# CEC1736_S0_2HW device description
Architecture: CORTEX-M4; Family: CEC173X; Series: CEC
Registers are 32-bit, read-write, reset 0x0 unless marked. A register's access mark holds for its fields unless they carry their own. Offsets are from the block's base; [hi:lo] are bit positions; lines under a group give offsets from that group; {n}, {i} and the like mark numbered series; 'fields as' and 'values as' point back to an identical list.

## SPI_MON — SPI Monitor Block
Instances: SPI_MON0 0x40010000, SPI_MON1 0x40010400
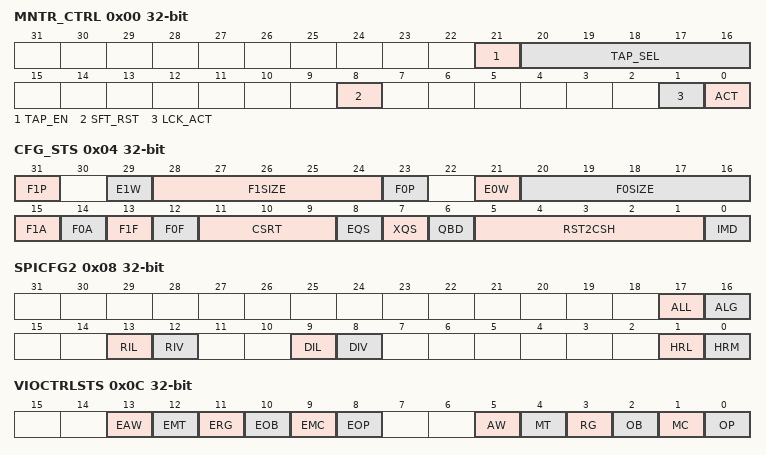
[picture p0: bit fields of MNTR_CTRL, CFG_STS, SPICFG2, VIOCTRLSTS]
0x00 MNTR_CTRL — SPI Monitor Control Register
  [21] TAP_EN — CPTR_CLK_TAP_EN enable the delay taps. It is recommended that a customer set the TAP_EN bit to 1, and the TAP_SEL field to 04h.
  [20:16] TAP_SEL — CPTR_CLK_TAP_SEL selects which 0.5ns delay tap to have the capture clock on. 00h = 0 ns delay (or if TAP_EN = 0). 01h = 0.5ns nom delay; +/- 50% 02h = 1.0ns 03h = 1.5ns 04h = 2.0ns etc. 1Fh = 15.5ns
  [8] SFT_RST — Soft Reset. This field is auto cleared by hardware. 1= Soft Reset SPI Monitor, 0 = No Effect
  [1] LCK_ACT — Lock Activate 1= Activate field Locked, 0= Activate field unlocked
  [0] ACT — Activate 1= Activate, 0= De-activate
0x04 CFG_STS — SPI Configuration Status Register
  [31] F1P — Flash 1 Present. 0=Not Present, 1=Present
  [29] E1W — Enable Wrap Detection. 0=Disable, 1=Enable
  [28:24] F1SIZE — Flash 1 Size. Flash sizes are expressed in bytes as a power of 2, matching a Flash Get-ID convention. For the most common cases: 17h = 23d => 2^23 = 8MByte 18h = 24d => 2^24 = 16MByte 19h = 25d => 2^25 = 32MByte 1Ah = 26d => 2^26 = 64MByte
  [23] F0P — Flash 0 Present. 0=Not Present, 1=Present
  [21] E0W — Enable Wrap Detection. 0=Disable, 1=Enable.
  [20:16] F0SIZE — Flash 0 Size. Flash sizes are expressed in bytes as a power of 2, matching a Flash Get-ID convention. For the most common cases: 17h = 23d => 2^23 = 8MByte 18h = 24d => 2^24 = 16MByte 19h = 25d => 2^25 = 32MByte 1Ah = 26d => 2^26 = 64MByte
  [15] F1A — Set 3B/4B Address Mode for Flash 1. 0=3B Address Mode, 1=4B Address Mode
  [14] F0A — Set 3B/4B Address Mode for Flash 0. 0=3B Address Mode, 1=4B Address Mode
  [13] F1F — Enable following of Address Mode. (SPI Snooping) for each Flash. 0=Disable, 1=Enable
  [12] F0F — Enable following of Address Mode. (SPI Snooping) for each Flash. 0=Disable, 1=Enable
  [11:9] CSRT — Chip Select Routing. 000 = Both CSn#_In pass directly to CSn# Out, both enabled out. 001 = CS1n_In passes to CS1# Output, but CS0# Output is disabled (floats high). 010 = CS0n_In passes to CS0# Output, but CS1# Output is disabled (floats high). 100 = Swap CS1#/CS0#_In to CS0#/CS1# Out respectively, both enabled out. 101 = CS0n_In passes to CS1# Out, and CS0# Output is disabled (floats high). 110 = CS1n_In passes to CS0# Out, and CS1# Output is disabled (floats high). x11 = CS0n/CS1n Outputs are both disabled (floating high) regardless of inputs.
  [8] EQS — Enable Q-Switch (Isolator) to Host. 0 = Disable, 1 = Enable.
  [7] XQS — Cross-Over Q-Switch status. (BMC->CPU). RO image of Interbus bit which as 1 overrides EQS bit at both SPI buses without changing their states.
  [6] QBD — Quad Bus Disable, 1 = Half Bus Mode, 0 = IO[3:0] are all controlled by EQS.
  [5:1] RST2CSH — RESET# to CS# High Delay. 2^n x 20us, 00h=20us, 1Fh= 1.3sec. IRQ triggers at this point also.
  [0] IMD — Flash Intervention Mode. 0 = Power-Off (POR), 1 = RESET# Pulse
0x08 SPICFG2 — SPI Monitor Configuration 2 Register
  [17] ALL — ALG Bit Lock. 0 = Unlocked, 1 = Locked.
  [16] ALG — Hash Algorithm Mode. 0 = SHA-384, 1 = Reserved
  [13] RIL — RIV Bit Lock. 0 = Unlocked, 1 = Locked.
  [12] RIV — Special Region InterVention Mode. If DIV=1 then RIV is ignored. If DIV=0 and RIV=1 then: Reads that are forbidden by the Runtime Region register set are only cancelled by gating off CSn# for that SPI command, and setting the IRQ. No system shutdown results, and subsequent legal Reads are allowed.
  [9] DIL — DIV Bit Lock. 0 = Unlocked, 1 = Locked.
  [8] DIV — Disable Inter Vention. 1 = IRQ-only Mode.
  [1] HRL — HRM Bit Lock. 0 = Unlocked, 1 = Locked.
  [0] HRM — Host Reset Mode. 0 = APn_RESET#, 1 = Pin.
0x0C VIOCTRLSTS — Violation IRQ Control/Status Register
  [13] EAW — Enable Address Wrap within a Flash device Interrupt. 0 = Disable, 1 = Enable
  [12] EMT — Enable Timeout in Match Phase Interrupt. 0 = Disable, 1 = Enable
  [11] ERG — Enable Runtime Region R/W Permission Violation Interrupt. 0 = Disable, 1 = Enable
  [10] EOB — Enable Out of Bounds Interrupt. 0 = Disable, 1 = Enable
  [9] EMC — Enable Data Mismatch Violation Interrupt. 0 = Disable, 1 = Enable
  [8] EOP — Enable Opcode Violation Interrupt. 0 = Disable, 1 = Enable
  [5] AW — Address Wrap within a Flash device.
  [4] MT — Timeout in Match Phase
  [3] RG — Runtime Region R/W Permission Violation
  [2] OB — Out of Bounds. Outside all Runtime Regions
  [1] MC — Data Mismatch Violation
  [0] OP — Opcode Violation
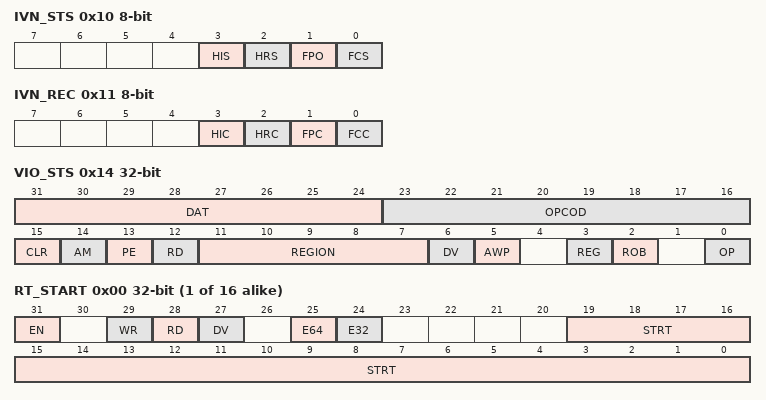
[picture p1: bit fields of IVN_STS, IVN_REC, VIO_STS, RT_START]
0x10 IVN_STS 8-bit ro — SPI Intervention Status Register
  [3] HIS — Host held Isolated
  [2] HRS — Host held in Reset
  [1] FPO — Flash Power or RESET# Activated.
  [0] FCS — Flash Chip Selects forced high and bus forced low.
0x11 IVN_REC 8-bit wo — SPI Intervention Recovery Register
  [3] HIC — Write 1 to clear HIS Host held Isolated
  [2] HRC — Write 1 to clear HRS Host held in Reset
  [1] FPC — Write 1 to clear FPO Flash Power or RESET# Activated.
  [0] FCC — Write 1 to clear FCS Flash Chip Selects forced high and bus forced low.
0x14 VIO_STS — Violation Log Register
  [31:24] DAT — SPI Data Byte
  [23:16] OPCOD — Flash Opcode
  [15] CLR — Clear Register RW1C. This bit is auto clearing
  [14] AM — Flash Address Mode
  [13] PE — Killed as a Program or Erase
  [12] RD — Killed as a Read
  [11:7] REGION — Region Number
  [6] DV — Device Number
  [5] AWP — Address Wrap
  [3] REG — Runtime Region Violation
  [2] ROB — Region Failure, Out of Bounds
  [0] OP — Opcode Violation
0x18 ERR_ADDR ro — Error Byte Address Register
  [31:0] ADDR — Byte address at which the error occurred, within the designated Flash
{0x20+0x80*i} FLASH_SET[{i}] (i=0..1) group — Per Flash Device Register Definition
  {0x0+4j} OP_PRMT[{j}] (j=0..7) — Permit Address Register
    [31:0] PRMT — Permit. Each array organized into 8 32-bit registers set per Flash device. 1 = Permit, and if not recognized then ignore. 0 = Kill immediately upon seeing this opcode.
  {0x20+4j} OP_KILLMD[{j}] (j=0..7) — Kill Address Register
    [31:0] KILL — Kill. Each array organized into 8 32-bit registers set per Flash device. 1 = If Killed, then kill as a Write: Holding CS# low. 0 = If Killed, then kill as a Read: Force CS# high first.
  {0x40+4j} OP_WPROT[{j}] (j=0..7) — Write Protect Address Register
    [31:0] WPROT — Write Protect. Each array organized into 8 32-bit registers set per Flash device. 1 = Make the corresponding bits RO in Permit and Killmd regs. 0 = Corresponding bits are R/W.
  {0x60+4j} OP_LOCK[{j}] (j=0..7) — Lock Address Register
    [31:0] LOCK — Lock. Each array organized into 8 32-bit registers set per Flash device. 1 = Make the corresponding bits RO in Permit and Killmd regs, overriding the Wprot register. Any 1 bit in this register is locked. 0 = Corresponding bits are R/W or RO, as determined by the Wprot register.
{0x120+8i} RN_TM[{i}] (i=0..15) group — Run Time Registers
  0x00 RT_START — Runtime Monitoring Start Register
    [31] EN — Enable Register Pair for Monitoring. 0 = No, 1 = Yes
    [29] WR — Write Allowed for Region. 0 = No, 1 = Yes
    [28] RD — Read Allowed for Region. 0 = No, 1 = Yes
    [27] DV — Flash Device 0 = CS0#, 1 = CS1#.
    [25] E64 — Enable 64KByte Erase opcode for this region. 0 = Disable, 1 = Enable
    [24] E32 — Enable 32KByte Erase opcode for this region. 0 = Disable, 1 = Enable
    [19:0] STRT — A Flash address shifted by 12 (4K byte units). Bottom 12 address bits are 000h
  0x04 RT_LIMIT — Runtime Monitoring Limit Register
    [19:0] LMT — Limit Register
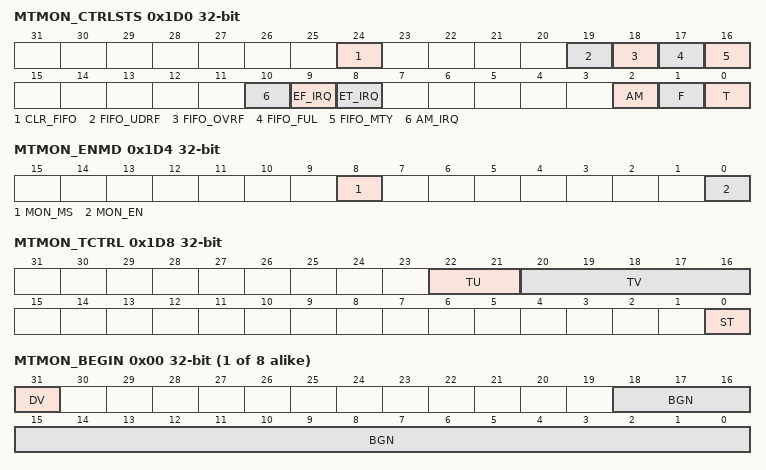
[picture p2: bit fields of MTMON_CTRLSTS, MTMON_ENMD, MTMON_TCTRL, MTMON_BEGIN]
0x1D0 MTMON_CTRLSTS — Match Monitor Control/Status Register
  [24] CLR_FIFO — Clear FIFO. This field is autocleared by hardware
  [19] FIFO_UDRF — FIFO Underflow
  [18] FIFO_OVRF — FIFO Overflow
  [17] FIFO_FUL — FIFO Full
  [16] FIFO_MTY — FIFO Empty
  [10] AM_IRQ — Enable 3B/4B Address Mode switch on either Flash Interrupt
  [9] EF_IRQ — Enable First Fetch in any Match region Interrupt
  [8] ET_IRQ — Enable Timeout Interrupt
  [2] AM — Set to 1 on a 3B/4B Address Mode switch on either Flash.
  [1] F — First Fetch in any Match region
  [0] T — Timeout
0x1D4 MTMON_ENMD — Match Monitor Enable/Mode Register
  [8] MON_MS — Match Pattern Source Mode: 0 = SRAM, 1 = Internal Flash.
  [0] MON_EN — Enable Data Matching. 0 = Disabled, 1 = Enabled
0x1D8 MTMON_TCTRL — Match Fetch Timeout Control Register
  [22:21] TU — Timeout Unit 00 = none (off), 01 = 32ms, 10 = 128ms, 11 = 1sec
  [20:16] TV — Timeout Value 0 to 32
  [0] ST — Start Timeout Counter
{0x1E0+0xC*i} MT_MON[{i}] (i=0..7) group — Match Monitor Region Registers
  0x00 MTMON_BEGIN — Match Monitor Region Begin Register
    [31] DV — Flash Device number, applying to both Begin and End fields 0 = CS0#, 1 = CS1#
    [18:0] BGN — The 19 bits of base address within the designated SPI Flash, specifying the last aligned 8K block.
  0x04 MTMON_END — Match Monitor Region End Register
    [18:0] END — The 19 bits of base address within the designated SPI Flash, specifying the last aligned 8K block.
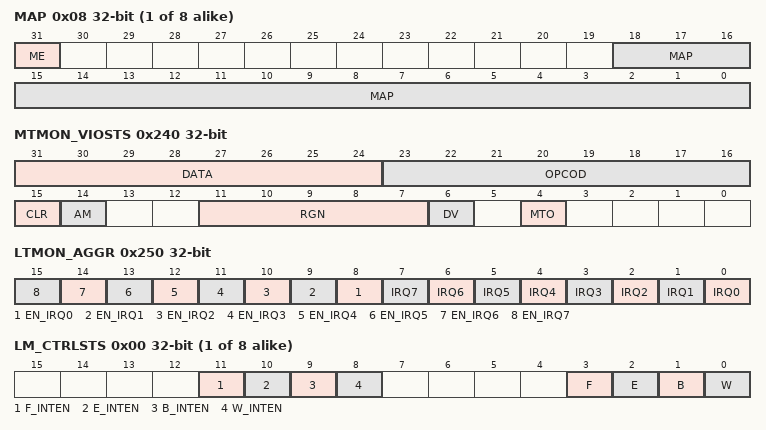
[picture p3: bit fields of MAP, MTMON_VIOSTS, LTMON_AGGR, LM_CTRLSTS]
  0x08 MAP — Match Monitor Region Map Register
    [31] ME — Match Enable for individual Region R
    [18:0] MAP — The 19 bits of base address within the designated SPI Flash, specifying the last aligned 8K block.
0x240 MTMON_VIOSTS — Match Monitor Violation Log Register
  [31:24] DATA — SPI Data Byte
  [23:16] OPCOD — Flash Opcode
  [15] CLR — Clear Register RW1C. This bit is auto clearing
  [14] AM — Flash Address Mode 0 = 3-byte, 1 = 4-byte
  [11:7] RGN — Region. This is read-Only bit. Shows which of 8 Match regions [7:0] got the mismatch.
  [6] DV — Device Number. This is read-Only bit. 0 = CS0, 1 = CS1.
  [4] MTO — Match Monitor Timeout. This is read-Only bit.
0x244 MTMON_VIOADDR ro — Match Monitor Violation Address Register
  fields as ERR_ADDR
0x250 LTMON_AGGR — Loadtime (Hash) IRQ Aggregation Register
  [n+8] EN_IRQ{n} (n=0..7) — Enable Load {n} Interrupt
  [n] IRQ{n} (n=0..7) — Load {n} Interrupt
{0x254+0x18*i} LT_MON[{i}] (i=0..7) group — Load Monitor Region Registers
  0x00 LM_CTRLSTS — Loadtime Monitor Control/Status Register
    [11] F_INTEN — Enable Finalized and result ready Interrupt
    [10] E_INTEN — Enable End Byte seen Interrupt
    [9] B_INTEN — Enable Begin Byte seen Interrupt
    [8] W_INTEN — Enable Waiting Interrupt
    [3] F — Finalized and result ready
    [2] E — End Byte seen
    [1] B — Begin Byte seen
    [0] W — Waiting
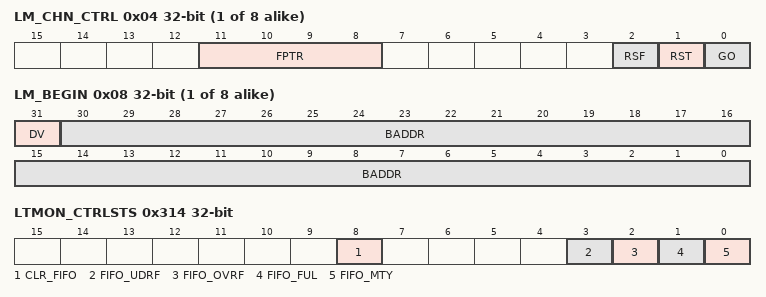
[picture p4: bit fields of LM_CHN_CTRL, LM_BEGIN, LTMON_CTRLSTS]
  0x04 LM_CHN_CTRL — Loadtime Monitor Channel Control Register
    [11:8] FPTR — FPTR: Result FIFO pointer. In 32Bit. Ranges: 0 to 11 for SHA-384 result 0 to 7 for SHA-256 result
    [2] RSF — RSF: Reset just Result FIFO pointer when this bit is set to 1
    [1] RST — RST: Stop and Reset calculation for this channel when set to 1
    [0] GO — GO: Run the Load Monitor for this channel
  0x08 LM_BEGIN — Loadtime Monitor Channel Begin Register
    [31] DV — Flash Device number, applying to both Begin and End fields. 0 = CS0#, 1 = CS1#
    [30:0] BADDR — A byte address within the designated Flash, specifying the first byte of the load image.
  0x0C LM_END — Loadtime Monitor Channel End Register
    [31:0] EADDR — A byte address within the designated Flash, specifying the last byte of the load image.
  0x10 LM_COUNT ro — Loadtime Monitor Channel Count Register
    [31:0] CNT — A Read-Only count of bytes processed.
  0x14 LM_DIGEST ro — Loadtime Monitor Channel Digest Register
    [31:0] DGST — A Read-Only FIFO Portal to Hash digest result. 12 or 8 Dwords depending on algorithm.
0x314 LTMON_CTRLSTS — Load Monitor Control/Status Register
  [8] CLR_FIFO — Clear FIFO
  [3] FIFO_UDRF — FIFO Underflow
  [2] FIFO_OVRF — FIFO Overflow
  [1] FIFO_FUL — FIFO Full
  [0] FIFO_MTY — FIFO Empty
